# STM32GBK1CBT6 register map
File version: 1.2
CPU: CM4 r0p1, little endian, MPU, FPU, 4 interrupt priority bits
Registers are 32-bit, read-write, reset 0x0 unless marked. A register's access mark holds for its fields unless they carry their own. Offsets are from the block's base; [hi:lo] are bit positions; {n}, {i} and the like mark numbered series.

## SPI1 — Serial peripheral interface/Inter-IC sound
Base 0x40013000
Same registers: SPI2 0x40003800, SPI3 0x40003C00
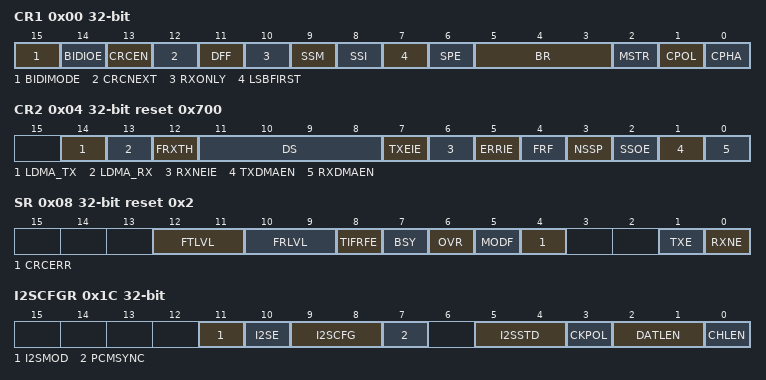
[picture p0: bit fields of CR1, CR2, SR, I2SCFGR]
0x00 CR1 — control register 1
  [15] BIDIMODE — Bidirectional data mode enable
  [14] BIDIOE — Output enable in bidirectional mode
  [13] CRCEN — Hardware CRC calculation enable
  [12] CRCNEXT — CRC transfer next
  [11] DFF — Data frame format
  [10] RXONLY — Receive only
  [9] SSM — Software slave management
  [8] SSI — Internal slave select
  [7] LSBFIRST — Frame format
  [6] SPE — SPI enable
  [5:3] BR — Baud rate control
  [2] MSTR — Master selection
  [1] CPOL — Clock polarity
  [0] CPHA — Clock phase
0x04 CR2 reset 0x700 — control register 2
  [14] LDMA_TX — Last DMA transfer for transmission
  [13] LDMA_RX — Last DMA transfer for reception
  [12] FRXTH — FIFO reception threshold
  [11:8] DS — Data size
  [7] TXEIE — Tx buffer empty interrupt enable
  [6] RXNEIE — RX buffer not empty interrupt enable
  [5] ERRIE — Error interrupt enable
  [4] FRF — Frame format
  [3] NSSP — NSS pulse management
  [2] SSOE — SS output enable
  [1] TXDMAEN — Tx buffer DMA enable
  [0] RXDMAEN — Rx buffer DMA enable
0x08 SR access per field reset 0x2 — status register
  [12:11] FTLVL ro — FIFO transmission level
  [10:9] FRLVL ro — FIFO reception level
  [8] TIFRFE ro — TI frame format error
  [7] BSY ro — Busy flag
  [6] OVR ro — Overrun flag
  [5] MODF ro — Mode fault
  [4] CRCERR rw — CRC error flag
  [1] TXE ro — Transmit buffer empty
  [0] RXNE ro — Receive buffer not empty
0x0C DR — data register
  [15:0] DR — Data register
0x10 CRCPR reset 0x7 — CRC polynomial register
  [15:0] CRCPOLY
0x14 RXCRCR ro — RX CRC register
  [15:0] RxCRC
0x18 TXCRCR ro — TX CRC register
  [15:0] TxCRC
0x1C I2SCFGR — configuration register
  [11] I2SMOD, [10] I2SE, [9:8] I2SCFG, [7] PCMSYNC, [5:4] I2SSTD, [3] CKPOL, [2:1] DATLEN, [0] CHLEN
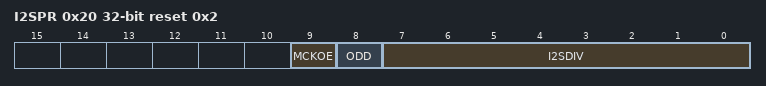
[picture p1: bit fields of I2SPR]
0x20 I2SPR reset 0x2 — prescaler register
  [9] MCKOE, [8] ODD, [7:0] I2SDIV

## EXTI — External interrupt/event controller
Base 0x40010400
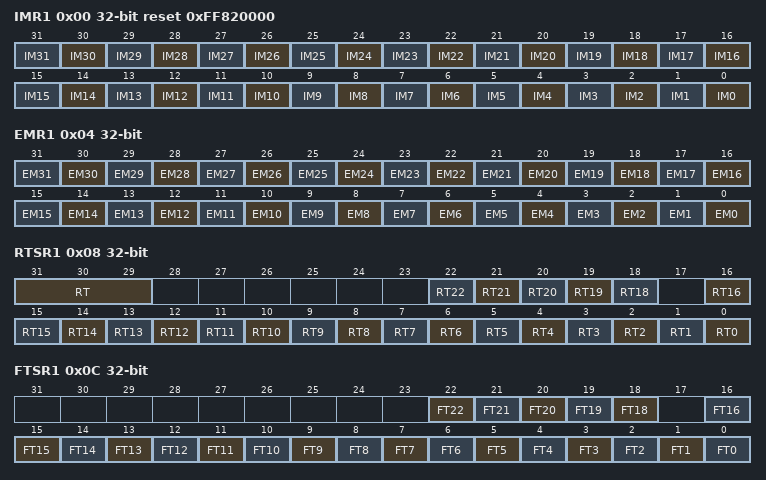
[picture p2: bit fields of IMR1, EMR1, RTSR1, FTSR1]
0x00 IMR1 reset 0xFF820000 — Interrupt mask register
  [n] IM{n} (n=0..31) — Interrupt Mask on line {n}
0x04 EMR1 — Event mask register
  [n] EM{n} (n=0..31) — Event Mask on line {n}
0x08 RTSR1 — Rising Trigger selection register
  [31:29] RT
  [n] RT{n} (n=18..22) — Rising trigger event configuration of line {n}
  [n] RT{n} (n=0..16) — Rising trigger event configuration of line {n}
0x0C FTSR1 — Falling Trigger selection register
  [n] FT{n} (n=18..22) — Falling trigger event configuration of line {n}
  [n] FT{n} (n=0..16) — Falling trigger event configuration of line {n}
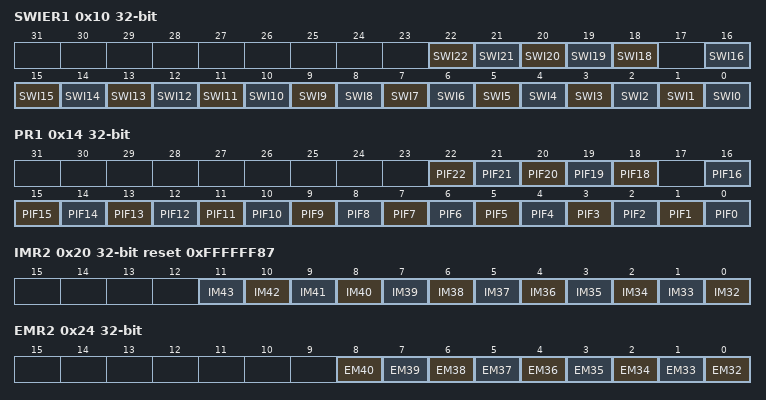
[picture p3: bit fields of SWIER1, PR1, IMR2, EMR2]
0x10 SWIER1 — Software interrupt event register
  [n] SWI{n} (n=18..22) — Software Interrupt on line {n}
  [n] SWI{n} (n=0..16) — Software Interrupt on line {n}
0x14 PR1 — Pending register
  [n] PIF{n} (n=18..22) — Pending bit {n}
  [n] PIF{n} (n=0..16) — Pending bit {n}
0x20 IMR2 reset 0xFFFFFF87 — Interrupt mask register
  [n-32] IM{n} (n=32..43) — Interrupt Mask on external/internal line {n}
0x24 EMR2 — Event mask register
  [n-32] EM{n} (n=32..40) — Event mask on external/internal line {n}
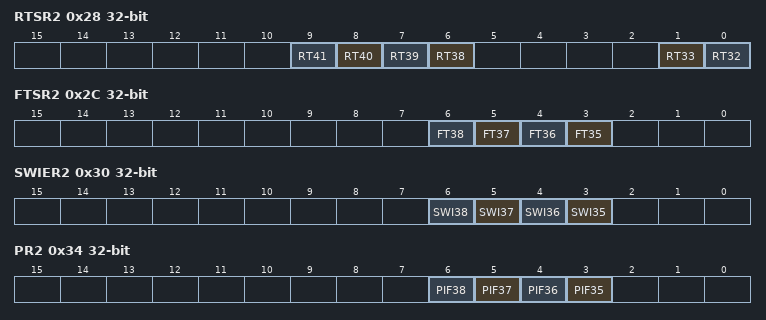
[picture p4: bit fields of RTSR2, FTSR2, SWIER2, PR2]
0x28 RTSR2 — Rising Trigger selection register
  [n-32] RT{n} (n=38..41) — Rising trigger event configuration bit of line {n}
  [1] RT33 — Rising trigger event configuration bit of line 32
  [0] RT32 — Rising trigger event configuration bit of line 32
0x2C FTSR2 — Falling Trigger selection register
  [n-32] FT{n} (n=35..38) — Falling trigger event configuration bit of line {n}
0x30 SWIER2 — Software interrupt event register
  [n-32] SWI{n} (n=35..38) — Software interrupt on line {n}
0x34 PR2 — Pending register
  [n-32] PIF{n} (n=35..38) — Pending interrupt flag on line {n}
